# bcm2837_lpa register map
Vendor: BROADCOM; Series: BCM2837; File version: A
BCM2837 found in the Raspberry Pi 3 and Zero 2W
CPU: CA72 r0p0, little endian, MPU, FPU, 2 interrupt priority bits
Registers are 32-bit, read-write, reset 0x0 unless marked. A register's access mark holds for its fields unless they carry their own. Offsets are from the block's base; lines under a group give offsets from that group; [hi:lo] are bit positions; {n}, {i} and the like mark numbered series; 'fields as' and 'values as' point back to an identical list; <NAME> marks a mode.

## Memory map
0x3F003000 SYSTMR size 0x80 — Broadcom System Timer
0x3F00B000 LIC size 0x400 — Broadcom Legacy Interrupt Controller
0x3F00B880 VCMAILBOX size 0x40 — Mailboxes for talking to/from VideoCore
0x3F101098 CM_PCM size 0x8 — Broadcom Clock Manager
0x3F1010A0 CM_PWM size 0x8
0x3F200000 GPIO size 0xF4 — Pin level and mux control
0x3F201000 UART0 blocks up to offset 0x4C — ARM Prime Cell PL011
0x3F204000 SPI0 size 0x200 — Broadcom SPI Controller
0x3F205000 BSC0 size 0x200 — Broadcom Serial Controller (I2C compatible)
0x3F20C000 PWM0 size 0x80 — Broadcom PWM
0x3F215000 AUX size 0x40 — Three auxiliary peripherals
0x3F215040 UART1 size 0x40 — Mini UART
0x3F215080 SPI1 size 0x40 — Aux SPI
0x3F2150C0 SPI2 size 0x40 — Aux SPI
0x3F300000 EMMC size 0x100 — Arasan SD3.0 Host AHB eMMC 4.4
0x3F804000 BSC1 size 0x200
0x3F805000 BSC2 size 0x200
0x3F980000 USB_OTG_GLOBAL size 0x131 — USB on the go high speed
0x3F980400 USB_OTG_HOST size 0x400 — USB on the go high speed
0x3F980800 USB_OTG_DEVICE size 0x400 — USB on the go high speed
0x3F980E00 USB_OTG_PWRCLK size 0x400 — USB on the go high speed power control

## Interrupts
0 TIMER_0 (SYSTMR) — Timer 0 matched
1 TIMER_1 (SYSTMR) — Timer 1 matched
2 TIMER_2 (SYSTMR) — Timer 2 matched
3 TIMER_3 (SYSTMR) — Timer 3 matched
9 USB (USB_OTG_GLOBAL) — USB interrupt
29 AUX — Interrupt from AUX
49 GPIO0 (GPIO) — Interrupt from bank 0
50 GPIO1 (GPIO) — Interrupt from bank 1
51 GPIO2 (GPIO) — Interrupt from bank 2
52 GPIO — OR of all GPIO interrupts
53 I2C (BSC0) — OR of all I2C interrupts
54 SPI (SPI0) — OR of all SPI interrupts except 1 and 2
57 UART (UART0) — OR of all UART interrupts except 1
62 EMMC — OR of EMMC and EMMC2

## VCMAILBOX — Mailboxes for talking to/from VideoCore
Base 0x3F00B880
0x00 READ ro reset not defined — Read messages from the VideoCore
0x10 PEEK0 access not given reset not defined
0x14 SENDER0 access not given reset not defined
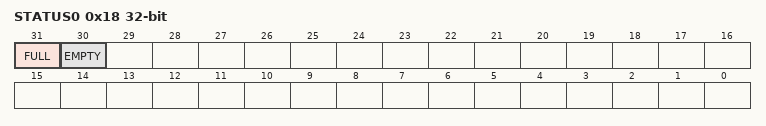
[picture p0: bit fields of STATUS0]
0x18 STATUS0 ro reset not defined
  [31] FULL, [30] EMPTY
0x1C CONFIG0 reset not defined
  [0] IRQEN — Enable the interrupt when data is available
0x20 WRITE wo reset not defined — Write messages to the VideoCore
0x30 PEEK1 access not given reset not defined
0x34 SENDER1 access not given reset not defined
0x38 STATUS1 access not given reset not defined
0x3C CONFIG1 access not given reset not defined

## CM_PCM — Broadcom Clock Manager
Base 0x3F101098
Same registers: CM_PWM 0x3F1010A0
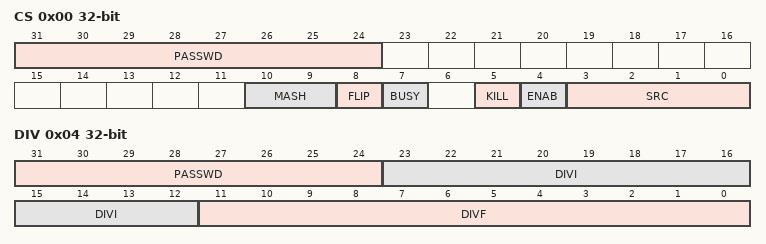
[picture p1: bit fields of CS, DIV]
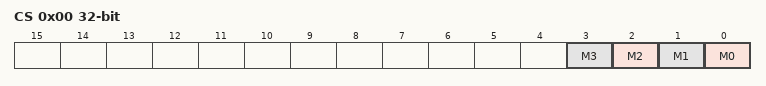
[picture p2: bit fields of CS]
0x00 CS — Control / Status
  [31:24] PASSWD wo — Password. Always 0x5a
    90=PASSWD
  [10:9] MASH — MASH control, stage count
  [8] FLIP — Generate an edge on output. (For testing)
  [7] BUSY ro — Indicates the clock generator is running
  [5] KILL — Stop and reset the generator
  [4] ENAB — Enable the clock generator. (Switch SRC first.)
  [3:0] SRC — Clock source
    other=GND; 1=XOSC; 2=TEST0; 3=TEST1; 4=PLLA; 5=PLLB; 6=PLLC; 7=HDMI
0x04 DIV — Clock divisor
  [31:24] PASSWD wo — Password. Always 0x5a
    90=PASSWD
  [23:12] DIVI — Integer part of divisor
  [11:0] DIVF — Fractional part of divisor

## SYSTMR — Broadcom System Timer
Base 0x3F003000
0x00 CS — Control / Status
  [n] M{n} write-1-clears (n=0..3) — System timer match {n}
0x04 CLO ro — Lower 32 bits for the free running counter
0x08 CHI ro — Higher 32 bits for the free running counter
{0xC+4i} C{i} (i=0..3) — Compare channel {i}

## UART0 — ARM Prime Cell PL011
Base 0x3F201000
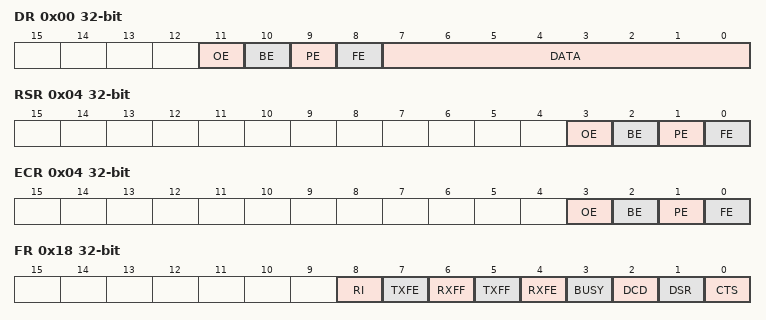
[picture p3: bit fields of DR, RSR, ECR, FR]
0x00 DR — Data Register
  [11] OE, [10] BE, [9] PE, [8] FE, [7:0] DATA
0x04 RSR ro — Receive Status Register
  [3] OE, [2] BE, [1] PE, [0] FE
0x04 ECR wo — Error Clear Register
  [3] OE, [2] BE, [1] PE, [0] FE
0x18 FR — Flag Register
  [8] RI, [7] TXFE, [6] RXFF, [5] TXFF, [4] RXFE, [3] BUSY, [2] DCD, [1] DSR, [0] CTS
0x24 IBRD — Integer Baud Rate Register
  [15:0] BAUDDIVINT
0x28 FBRD — Fractional Baud Rate Register
  [5:0] BAUDDIVFRAC
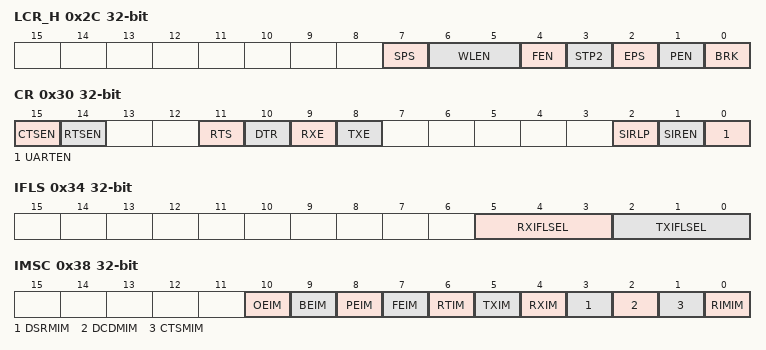
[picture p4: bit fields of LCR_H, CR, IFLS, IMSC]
0x2C LCR_H — Line Control Register
  [7] SPS, [6:5] WLEN, [4] FEN, [3] STP2, [2] EPS, [1] PEN, [0] BRK
0x30 CR — Control Register
  [15] CTSEN, [14] RTSEN, [11] RTS, [10] DTR, [9] RXE, [8] TXE, [2] SIRLP, [1] SIREN, [0] UARTEN
0x34 IFLS — Interrupt FIFO Level Select Register
  [5:3] RXIFLSEL, [2:0] TXIFLSEL
0x38 IMSC — Interrupt Mask set_Clear Register
  [10] OEIM, [9] BEIM, [8] PEIM, [7] FEIM, [6] RTIM, [5] TXIM, [4] RXIM, [3] DSRMIM, [2] DCDMIM, [1] CTSMIM, [0] RIMIM
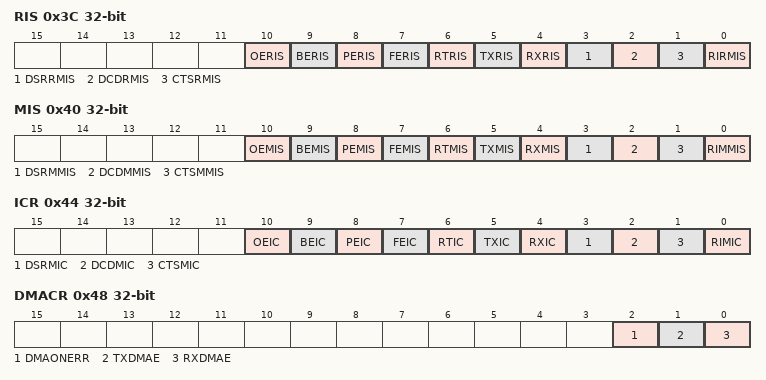
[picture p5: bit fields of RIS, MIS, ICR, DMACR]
0x3C RIS ro — Raw Interrupt Status Register
  [10] OERIS, [9] BERIS, [8] PERIS, [7] FERIS, [6] RTRIS, [5] TXRIS, [4] RXRIS, [3] DSRRMIS, [2] DCDRMIS, [1] CTSRMIS, [0] RIRMIS
0x40 MIS ro — Masked Interrupt Status Register
  [10] OEMIS, [9] BEMIS, [8] PEMIS, [7] FEMIS, [6] RTMIS, [5] TXMIS, [4] RXMIS, [3] DSRMMIS, [2] DCDMMIS, [1] CTSMMIS, [0] RIMMIS
0x44 ICR wo — Interrupt Clear Register
  [10] OEIC, [9] BEIC, [8] PEIC, [7] FEIC, [6] RTIC, [5] TXIC, [4] RXIC, [3] DSRMIC, [2] DCDMIC, [1] CTSMIC, [0] RIMIC
0x48 DMACR — DMA Control Register
  [2] DMAONERR, [1] TXDMAE, [0] RXDMAE
